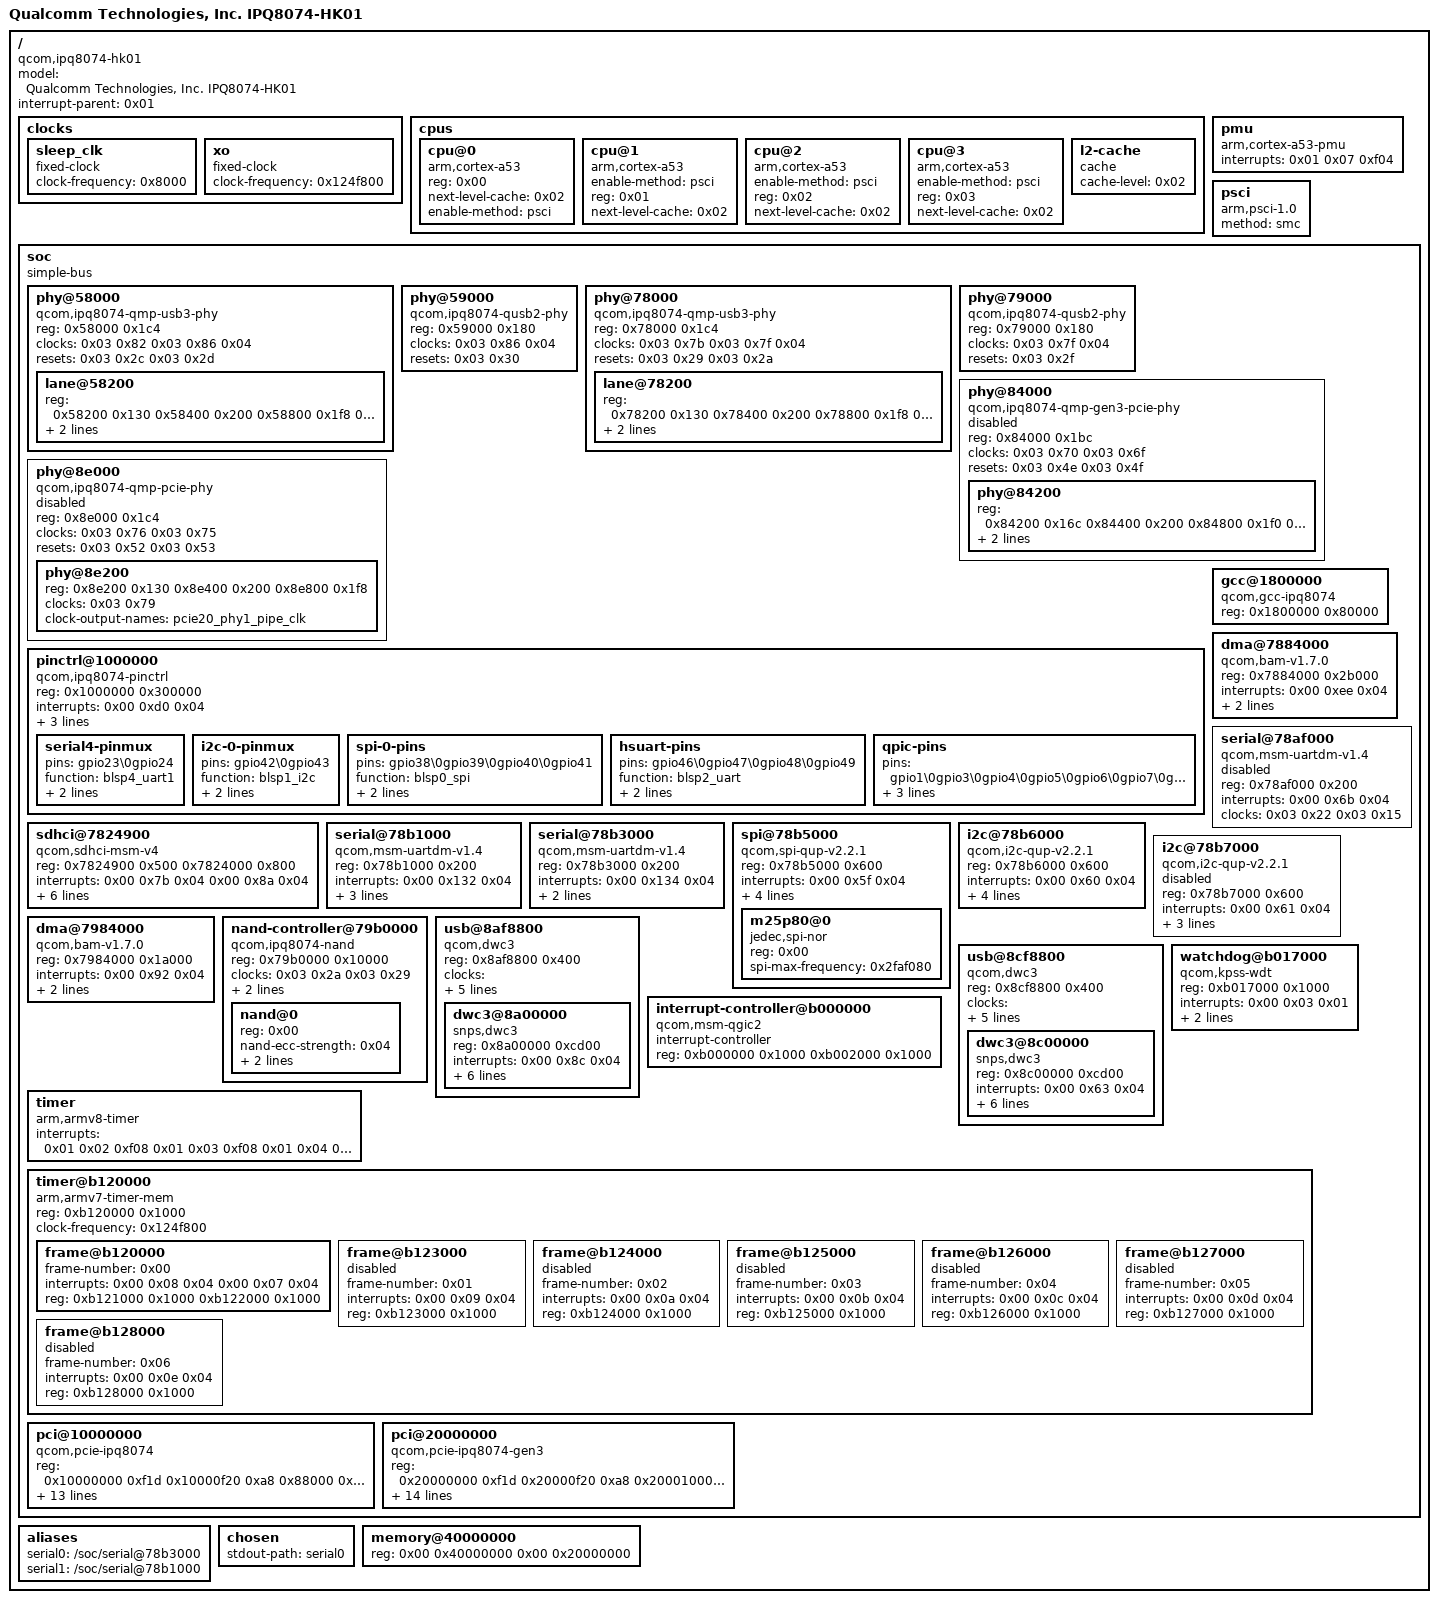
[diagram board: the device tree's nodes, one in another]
/dts-v1/;

/ {
	model = "Qualcomm Technologies, Inc. IPQ8074-HK01";
	compatible = "qcom,ipq8074-hk01\0qcom,ipq8074";
	#address-cells = <0x02>;
	#size-cells = <0x02>;
	interrupt-parent = <0x01>;

	clocks {

		sleep_clk {
			compatible = "fixed-clock";
			clock-frequency = <0x8000>;
			#clock-cells = <0x00>;
			phandle = <0x11>;
		};

		xo {
			compatible = "fixed-clock";
			clock-frequency = <0x124f800>;
			#clock-cells = <0x00>;
			phandle = <0x04>;
		};
	};

	cpus {
		#address-cells = <0x01>;
		#size-cells = <0x00>;

		cpu@0 {
			device_type = "cpu";
			compatible = "arm,cortex-a53";
			reg = <0x00>;
			next-level-cache = <0x02>;
			enable-method = "psci";
			phandle = <0x14>;
		};

		cpu@1 {
			device_type = "cpu";
			compatible = "arm,cortex-a53";
			enable-method = "psci";
			reg = <0x01>;
			next-level-cache = <0x02>;
			phandle = <0x15>;
		};

		cpu@2 {
			device_type = "cpu";
			compatible = "arm,cortex-a53";
			enable-method = "psci";
			reg = <0x02>;
			next-level-cache = <0x02>;
			phandle = <0x16>;
		};

		cpu@3 {
			device_type = "cpu";
			compatible = "arm,cortex-a53";
			enable-method = "psci";
			reg = <0x03>;
			next-level-cache = <0x02>;
			phandle = <0x17>;
		};

		l2-cache {
			compatible = "cache";
			cache-level = <0x02>;
			phandle = <0x02>;
		};
	};

	pmu {
		compatible = "arm,cortex-a53-pmu";
		interrupts = <0x01 0x07 0xf04>;
	};

	psci {
		compatible = "arm,psci-1.0";
		method = "smc";
	};

	soc {
		#address-cells = <0x01>;
		#size-cells = <0x01>;
		ranges = <0x00 0x00 0x00 0xffffffff>;
		compatible = "simple-bus";
		phandle = <0x18>;

		phy@58000 {
			compatible = "qcom,ipq8074-qmp-usb3-phy";
			reg = <0x58000 0x1c4>;
			#clock-cells = <0x01>;
			#address-cells = <0x01>;
			#size-cells = <0x01>;
			ranges;
			clocks = <0x03 0x82 0x03 0x86 0x04>;
			clock-names = "aux\0cfg_ahb\0ref";
			resets = <0x03 0x2c 0x03 0x2d>;
			reset-names = "phy\0common";
			status = "okay";
			phandle = <0x19>;

			lane@58200 {
				reg = <0x58200 0x130 0x58400 0x200 0x58800 0x1f8 0x58600 0x44>;
				#phy-cells = <0x00>;
				clocks = <0x03 0x87>;
				clock-names = "pipe0";
				clock-output-names = "usb3phy_1_cc_pipe_clk";
				phandle = <0x10>;
			};
		};

		phy@59000 {
			compatible = "qcom,ipq8074-qusb2-phy";
			reg = <0x59000 0x180>;
			#phy-cells = <0x00>;
			clocks = <0x03 0x86 0x04>;
			clock-names = "cfg_ahb\0ref";
			resets = <0x03 0x30>;
			status = "okay";
			phandle = <0x0f>;
		};

		phy@78000 {
			compatible = "qcom,ipq8074-qmp-usb3-phy";
			reg = <0x78000 0x1c4>;
			#clock-cells = <0x01>;
			#address-cells = <0x01>;
			#size-cells = <0x01>;
			ranges;
			clocks = <0x03 0x7b 0x03 0x7f 0x04>;
			clock-names = "aux\0cfg_ahb\0ref";
			resets = <0x03 0x29 0x03 0x2a>;
			reset-names = "phy\0common";
			status = "okay";
			phandle = <0x1a>;

			lane@78200 {
				reg = <0x78200 0x130 0x78400 0x200 0x78800 0x1f8 0x78600 0x44>;
				#phy-cells = <0x00>;
				clocks = <0x03 0x80>;
				clock-names = "pipe0";
				clock-output-names = "usb3phy_0_cc_pipe_clk";
				phandle = <0x0e>;
			};
		};

		phy@79000 {
			compatible = "qcom,ipq8074-qusb2-phy";
			reg = <0x79000 0x180>;
			#phy-cells = <0x00>;
			clocks = <0x03 0x7f 0x04>;
			clock-names = "cfg_ahb\0ref";
			resets = <0x03 0x2f>;
			status = "okay";
			phandle = <0x0d>;
		};

		phy@84000 {
			compatible = "qcom,ipq8074-qmp-gen3-pcie-phy";
			reg = <0x84000 0x1bc>;
			#address-cells = <0x01>;
			#size-cells = <0x01>;
			ranges;
			clocks = <0x03 0x70 0x03 0x6f>;
			clock-names = "aux\0cfg_ahb";
			resets = <0x03 0x4e 0x03 0x4f>;
			reset-names = "phy\0common";
			status = "disabled";
			phandle = <0x1b>;

			phy@84200 {
				reg = <0x84200 0x16c 0x84400 0x200 0x84800 0x1f0 0x84c00 0xf4>;
				#phy-cells = <0x00>;
				#clock-cells = <0x00>;
				clocks = <0x03 0x73>;
				clock-names = "pipe0";
				clock-output-names = "pcie20_phy0_pipe_clk";
				status = "okay";
				phandle = <0x13>;
			};
		};

		phy@8e000 {
			compatible = "qcom,ipq8074-qmp-pcie-phy";
			reg = <0x8e000 0x1c4>;
			#address-cells = <0x01>;
			#size-cells = <0x01>;
			ranges;
			clocks = <0x03 0x76 0x03 0x75>;
			clock-names = "aux\0cfg_ahb";
			resets = <0x03 0x52 0x03 0x53>;
			reset-names = "phy\0common";
			status = "disabled";
			phandle = <0x1c>;

			phy@8e200 {
				reg = <0x8e200 0x130 0x8e400 0x200 0x8e800 0x1f8>;
				#phy-cells = <0x00>;
				#clock-cells = <0x00>;
				clocks = <0x03 0x79>;
				clock-names = "pipe0";
				clock-output-names = "pcie20_phy1_pipe_clk";
				status = "okay";
				phandle = <0x12>;
			};
		};

		pinctrl@1000000 {
			compatible = "qcom,ipq8074-pinctrl";
			reg = <0x1000000 0x300000>;
			interrupts = <0x00 0xd0 0x04>;
			gpio-controller;
			gpio-ranges = <0x05 0x00 0x00 0x46>;
			#gpio-cells = <0x02>;
			interrupt-controller;
			#interrupt-cells = <0x02>;
			phandle = <0x05>;

			serial4-pinmux {
				pins = "gpio23\0gpio24";
				function = "blsp4_uart1";
				drive-strength = <0x08>;
				bias-disable;
				phandle = <0x08>;
			};

			i2c-0-pinmux {
				pins = "gpio42\0gpio43";
				function = "blsp1_i2c";
				drive-strength = <0x08>;
				bias-disable;
				phandle = <0x0a>;
			};

			spi-0-pins {
				pins = "gpio38\0gpio39\0gpio40\0gpio41";
				function = "blsp0_spi";
				drive-strength = <0x08>;
				bias-disable;
				phandle = <0x09>;
			};

			hsuart-pins {
				pins = "gpio46\0gpio47\0gpio48\0gpio49";
				function = "blsp2_uart";
				drive-strength = <0x08>;
				bias-disable;
				phandle = <0x07>;
			};

			qpic-pins {
				pins = "gpio1\0gpio3\0gpio4\0gpio5\0gpio6\0gpio7\0gpio8\0gpio10\0gpio11\0gpio12\0gpio13\0gpio14\0gpio15\0gpio16\0gpio17";
				function = "qpic";
				drive-strength = <0x08>;
				bias-disable;
				phandle = <0x0c>;
			};
		};

		gcc@1800000 {
			compatible = "qcom,gcc-ipq8074";
			reg = <0x1800000 0x80000>;
			#clock-cells = <0x01>;
			#reset-cells = <0x01>;
			phandle = <0x03>;
		};

		sdhci@7824900 {
			compatible = "qcom,sdhci-msm-v4";
			reg = <0x7824900 0x500 0x7824000 0x800>;
			reg-names = "hc_mem\0core_mem";
			interrupts = <0x00 0x7b 0x04 0x00 0x8a 0x04>;
			interrupt-names = "hc_irq\0pwr_irq";
			clocks = <0x04 0x03 0x89 0x03 0x8a>;
			clock-names = "xo\0iface\0core";
			max-frequency = <0x16e36000>;
			mmc-ddr-1_8v;
			mmc-hs200-1_8v;
			mmc-hs400-1_8v;
			bus-width = <0x08>;
			status = "okay";
			phandle = <0x1d>;
		};

		dma@7884000 {
			compatible = "qcom,bam-v1.7.0";
			reg = <0x7884000 0x2b000>;
			interrupts = <0x00 0xee 0x04>;
			clocks = <0x03 0x15>;
			clock-names = "bam_clk";
			#dma-cells = <0x01>;
			qcom,ee = <0x00>;
			phandle = <0x06>;
		};

		serial@78af000 {
			compatible = "qcom,msm-uartdm-v1.4\0qcom,msm-uartdm";
			reg = <0x78af000 0x200>;
			interrupts = <0x00 0x6b 0x04>;
			clocks = <0x03 0x22 0x03 0x15>;
			clock-names = "core\0iface";
			status = "disabled";
			phandle = <0x1e>;
		};

		serial@78b1000 {
			compatible = "qcom,msm-uartdm-v1.4\0qcom,msm-uartdm";
			reg = <0x78b1000 0x200>;
			interrupts = <0x00 0x132 0x04>;
			clocks = <0x03 0x24 0x03 0x15>;
			clock-names = "core\0iface";
			dmas = <0x06 0x04 0x06 0x05>;
			dma-names = "tx\0rx";
			pinctrl-0 = <0x07>;
			pinctrl-names = "default";
			status = "okay";
			phandle = <0x1f>;
		};

		serial@78b3000 {
			compatible = "qcom,msm-uartdm-v1.4\0qcom,msm-uartdm";
			reg = <0x78b3000 0x200>;
			interrupts = <0x00 0x134 0x04>;
			clocks = <0x03 0x26 0x03 0x15>;
			clock-names = "core\0iface";
			pinctrl-0 = <0x08>;
			pinctrl-names = "default";
			status = "okay";
			phandle = <0x20>;
		};

		spi@78b5000 {
			compatible = "qcom,spi-qup-v2.2.1";
			#address-cells = <0x01>;
			#size-cells = <0x00>;
			reg = <0x78b5000 0x600>;
			interrupts = <0x00 0x5f 0x04>;
			spi-max-frequency = <0x2faf080>;
			clocks = <0x03 0x17 0x03 0x15>;
			clock-names = "core\0iface";
			dmas = <0x06 0x0c 0x06 0x0d>;
			dma-names = "tx\0rx";
			pinctrl-0 = <0x09>;
			pinctrl-names = "default";
			status = "okay";
			phandle = <0x21>;

			m25p80@0 {
				#address-cells = <0x01>;
				#size-cells = <0x01>;
				compatible = "jedec,spi-nor";
				reg = <0x00>;
				spi-max-frequency = <0x2faf080>;
			};
		};

		i2c@78b6000 {
			compatible = "qcom,i2c-qup-v2.2.1";
			#address-cells = <0x01>;
			#size-cells = <0x00>;
			reg = <0x78b6000 0x600>;
			interrupts = <0x00 0x60 0x04>;
			clocks = <0x03 0x15 0x03 0x18>;
			clock-names = "iface\0core";
			clock-frequency = <0x61a80>;
			dmas = <0x06 0x0f 0x06 0x0e>;
			dma-names = "rx\0tx";
			pinctrl-0 = <0x0a>;
			pinctrl-names = "default";
			status = "okay";
			phandle = <0x22>;
		};

		i2c@78b7000 {
			compatible = "qcom,i2c-qup-v2.2.1";
			#address-cells = <0x01>;
			#size-cells = <0x00>;
			reg = <0x78b7000 0x600>;
			interrupts = <0x00 0x61 0x04>;
			clocks = <0x03 0x15 0x03 0x1a>;
			clock-names = "iface\0core";
			clock-frequency = <0x186a0>;
			dmas = <0x06 0x11 0x06 0x10>;
			dma-names = "rx\0tx";
			status = "disabled";
			phandle = <0x23>;
		};

		dma@7984000 {
			compatible = "qcom,bam-v1.7.0";
			reg = <0x7984000 0x1a000>;
			interrupts = <0x00 0x92 0x04>;
			clocks = <0x03 0x29>;
			clock-names = "bam_clk";
			#dma-cells = <0x01>;
			qcom,ee = <0x00>;
			status = "okay";
			phandle = <0x0b>;
		};

		nand-controller@79b0000 {
			compatible = "qcom,ipq8074-nand";
			reg = <0x79b0000 0x10000>;
			#address-cells = <0x01>;
			#size-cells = <0x00>;
			clocks = <0x03 0x2a 0x03 0x29>;
			clock-names = "core\0aon";
			dmas = <0x0b 0x00 0x0b 0x01 0x0b 0x02>;
			dma-names = "tx\0rx\0cmd";
			pinctrl-0 = <0x0c>;
			pinctrl-names = "default";
			status = "okay";
			phandle = <0x24>;

			nand@0 {
				reg = <0x00>;
				nand-ecc-strength = <0x04>;
				nand-ecc-step-size = <0x200>;
				nand-bus-width = <0x08>;
			};
		};

		usb@8af8800 {
			compatible = "qcom,dwc3";
			reg = <0x8af8800 0x400>;
			#address-cells = <0x01>;
			#size-cells = <0x01>;
			ranges;
			clocks = <0x03 0x7c 0x03 0x7d 0x03 0x81 0x03 0x7e>;
			clock-names = "sys_noc_axi\0master\0sleep\0mock_utmi";
			assigned-clocks = <0x03 0x7c 0x03 0x7d 0x03 0x7e>;
			assigned-clock-rates = <0x7f27450 0x7f27450 0x124f800>;
			resets = <0x03 0x2b>;
			status = "okay";
			phandle = <0x25>;

			dwc3@8a00000 {
				compatible = "snps,dwc3";
				reg = <0x8a00000 0xcd00>;
				interrupts = <0x00 0x8c 0x04>;
				phys = <0x0d 0x0e>;
				phy-names = "usb2-phy\0usb3-phy";
				snps,is-utmi-l1-suspend;
				snps,hird-threshold = [00];
				snps,dis_u2_susphy_quirk;
				snps,dis_u3_susphy_quirk;
				dr_mode = "host";
				phandle = <0x26>;
			};
		};

		usb@8cf8800 {
			compatible = "qcom,dwc3";
			reg = <0x8cf8800 0x400>;
			#address-cells = <0x01>;
			#size-cells = <0x01>;
			ranges;
			clocks = <0x03 0x83 0x03 0x84 0x03 0x88 0x03 0x85>;
			clock-names = "sys_noc_axi\0master\0sleep\0mock_utmi";
			assigned-clocks = <0x03 0x83 0x03 0x84 0x03 0x85>;
			assigned-clock-rates = <0x7f27450 0x7f27450 0x124f800>;
			resets = <0x03 0x2e>;
			status = "okay";
			phandle = <0x27>;

			dwc3@8c00000 {
				compatible = "snps,dwc3";
				reg = <0x8c00000 0xcd00>;
				interrupts = <0x00 0x63 0x04>;
				phys = <0x0f 0x10>;
				phy-names = "usb2-phy\0usb3-phy";
				snps,is-utmi-l1-suspend;
				snps,hird-threshold = [00];
				snps,dis_u2_susphy_quirk;
				snps,dis_u3_susphy_quirk;
				dr_mode = "host";
				phandle = <0x28>;
			};
		};

		interrupt-controller@b000000 {
			compatible = "qcom,msm-qgic2";
			interrupt-controller;
			#interrupt-cells = <0x03>;
			reg = <0xb000000 0x1000 0xb002000 0x1000>;
			phandle = <0x01>;
		};

		timer {
			compatible = "arm,armv8-timer";
			interrupts = <0x01 0x02 0xf08 0x01 0x03 0xf08 0x01 0x04 0xf08 0x01 0x01 0xf08>;
		};

		watchdog@b017000 {
			compatible = "qcom,kpss-wdt";
			reg = <0xb017000 0x1000>;
			interrupts = <0x00 0x03 0x01>;
			clocks = <0x11>;
			timeout-sec = <0x1e>;
			phandle = <0x29>;
		};

		timer@b120000 {
			#address-cells = <0x01>;
			#size-cells = <0x01>;
			ranges;
			compatible = "arm,armv7-timer-mem";
			reg = <0xb120000 0x1000>;
			clock-frequency = <0x124f800>;

			frame@b120000 {
				frame-number = <0x00>;
				interrupts = <0x00 0x08 0x04 0x00 0x07 0x04>;
				reg = <0xb121000 0x1000 0xb122000 0x1000>;
			};

			frame@b123000 {
				frame-number = <0x01>;
				interrupts = <0x00 0x09 0x04>;
				reg = <0xb123000 0x1000>;
				status = "disabled";
			};

			frame@b124000 {
				frame-number = <0x02>;
				interrupts = <0x00 0x0a 0x04>;
				reg = <0xb124000 0x1000>;
				status = "disabled";
			};

			frame@b125000 {
				frame-number = <0x03>;
				interrupts = <0x00 0x0b 0x04>;
				reg = <0xb125000 0x1000>;
				status = "disabled";
			};

			frame@b126000 {
				frame-number = <0x04>;
				interrupts = <0x00 0x0c 0x04>;
				reg = <0xb126000 0x1000>;
				status = "disabled";
			};

			frame@b127000 {
				frame-number = <0x05>;
				interrupts = <0x00 0x0d 0x04>;
				reg = <0xb127000 0x1000>;
				status = "disabled";
			};

			frame@b128000 {
				frame-number = <0x06>;
				interrupts = <0x00 0x0e 0x04>;
				reg = <0xb128000 0x1000>;
				status = "disabled";
			};
		};

		pci@10000000 {
			compatible = "qcom,pcie-ipq8074";
			reg = <0x10000000 0xf1d 0x10000f20 0xa8 0x88000 0x2000 0x10100000 0x1000>;
			reg-names = "dbi\0elbi\0parf\0config";
			device_type = "pci";
			linux,pci-domain = <0x01>;
			bus-range = <0x00 0xff>;
			num-lanes = <0x01>;
			#address-cells = <0x03>;
			#size-cells = <0x02>;
			phys = <0x12>;
			phy-names = "pciephy";
			ranges = <0x81000000 0x00 0x10200000 0x10200000 0x00 0x10000 0x82000000 0x00 0x10220000 0x10220000 0x00 0xfde0000>;
			interrupts = <0x00 0x55 0x04>;
			interrupt-names = "msi";
			#interrupt-cells = <0x01>;
			interrupt-map-mask = <0x00 0x00 0x00 0x07>;
			interrupt-map = <0x00 0x00 0x00 0x01 0x01 0x00 0x8e 0x04 0x00 0x00 0x00 0x02 0x01 0x00 0x8f 0x04 0x00 0x00 0x00 0x03 0x01 0x00 0x90 0x04 0x00 0x00 0x00 0x04 0x01 0x00 0x91 0x04>;
			clocks = <0x03 0x7a 0x03 0x77 0x03 0x78 0x03 0x75 0x03 0x76>;
			clock-names = "iface\0axi_m\0axi_s\0ahb\0aux";
			resets = <0x03 0x7c 0x03 0x7d 0x03 0x7e 0x03 0x7f 0x03 0x80 0x03 0x81 0x03 0x82>;
			reset-names = "pipe\0sleep\0sticky\0axi_m\0axi_s\0ahb\0axi_m_sticky";
			status = "okay";
			perst-gpio = <0x05 0x3a 0x01>;
			phandle = <0x2a>;
		};

		pci@20000000 {
			compatible = "qcom,pcie-ipq8074-gen3";
			reg = <0x20000000 0xf1d 0x20000f20 0xa8 0x20001000 0x1000 0x80000 0x4000 0x20100000 0x1000>;
			reg-names = "dbi\0elbi\0atu\0parf\0config";
			device_type = "pci";
			linux,pci-domain = <0x00>;
			bus-range = <0x00 0xff>;
			num-lanes = <0x01>;
			max-link-speed = <0x03>;
			#address-cells = <0x03>;
			#size-cells = <0x02>;
			phys = <0x13>;
			phy-names = "pciephy";
			ranges = <0x81000000 0x00 0x20200000 0x20200000 0x00 0x10000 0x82000000 0x00 0x20220000 0x20220000 0x00 0xfde0000>;
			interrupts = <0x00 0x34 0x04>;
			interrupt-names = "msi";
			#interrupt-cells = <0x01>;
			interrupt-map-mask = <0x00 0x00 0x00 0x07>;
			interrupt-map = <0x00 0x00 0x00 0x01 0x01 0x00 0x4b 0x04 0x00 0x00 0x00 0x02 0x01 0x00 0x4e 0x04 0x00 0x00 0x00 0x03 0x01 0x00 0x4f 0x04 0x00 0x00 0x00 0x04 0x01 0x00 0x53 0x04>;
			clocks = <0x03 0x74 0x03 0x71 0x03 0x72 0x03 0xe0 0x03 0xe2>;
			clock-names = "iface\0axi_m\0axi_s\0axi_bridge\0rchng";
			resets = <0x03 0x75 0x03 0x76 0x03 0x77 0x03 0x78 0x03 0x79 0x03 0x7a 0x03 0x7b 0x03 0x83>;
			reset-names = "pipe\0sleep\0sticky\0axi_m\0axi_s\0ahb\0axi_m_sticky\0axi_s_sticky";
			status = "okay";
			perst-gpio = <0x05 0x3d 0x01>;
			phandle = <0x2b>;
		};
	};

	aliases {
		serial0 = "/soc/serial@78b3000";
		serial1 = "/soc/serial@78b1000";
	};

	chosen {
		stdout-path = "serial0";
	};

	memory@40000000 {
		device_type = "memory";
		reg = <0x00 0x40000000 0x00 0x20000000>;
	};

	__symbols__ {
		sleep_clk = "/clocks/sleep_clk";
		xo = "/clocks/xo";
		CPU0 = "/cpus/cpu@0";
		CPU1 = "/cpus/cpu@1";
		CPU2 = "/cpus/cpu@2";
		CPU3 = "/cpus/cpu@3";
		L2_0 = "/cpus/l2-cache";
		soc = "/soc";
		ssphy_1 = "/soc/phy@58000";
		usb1_ssphy = "/soc/phy@58000/lane@58200";
		qusb_phy_1 = "/soc/phy@59000";
		ssphy_0 = "/soc/phy@78000";
		usb0_ssphy = "/soc/phy@78000/lane@78200";
		qusb_phy_0 = "/soc/phy@79000";
		pcie_qmp0 = "/soc/phy@84000";
		pcie_phy0 = "/soc/phy@84000/phy@84200";
		pcie_qmp1 = "/soc/phy@8e000";
		pcie_phy1 = "/soc/phy@8e000/phy@8e200";
		tlmm = "/soc/pinctrl@1000000";
		serial_4_pins = "/soc/pinctrl@1000000/serial4-pinmux";
		i2c_0_pins = "/soc/pinctrl@1000000/i2c-0-pinmux";
		spi_0_pins = "/soc/pinctrl@1000000/spi-0-pins";
		hsuart_pins = "/soc/pinctrl@1000000/hsuart-pins";
		qpic_pins = "/soc/pinctrl@1000000/qpic-pins";
		gcc = "/soc/gcc@1800000";
		sdhc_1 = "/soc/sdhci@7824900";
		blsp_dma = "/soc/dma@7884000";
		blsp1_uart1 = "/soc/serial@78af000";
		blsp1_uart3 = "/soc/serial@78b1000";
		blsp1_uart5 = "/soc/serial@78b3000";
		blsp1_spi1 = "/soc/spi@78b5000";
		blsp1_i2c2 = "/soc/i2c@78b6000";
		blsp1_i2c3 = "/soc/i2c@78b7000";
		qpic_bam = "/soc/dma@7984000";
		qpic_nand = "/soc/nand-controller@79b0000";
		usb_0 = "/soc/usb@8af8800";
		dwc_0 = "/soc/usb@8af8800/dwc3@8a00000";
		usb_1 = "/soc/usb@8cf8800";
		dwc_1 = "/soc/usb@8cf8800/dwc3@8c00000";
		intc = "/soc/interrupt-controller@b000000";
		watchdog = "/soc/watchdog@b017000";
		pcie1 = "/soc/pci@10000000";
		pcie0 = "/soc/pci@20000000";
	};
};
